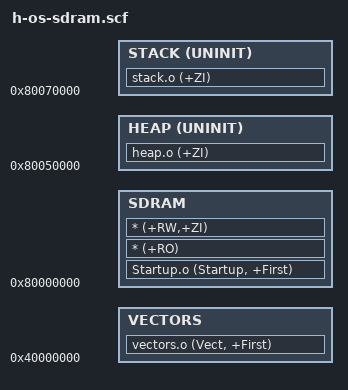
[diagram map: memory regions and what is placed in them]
;*
;*//**********************************************************************************
;*                                        H-OS
;*                                The Real-Time Kernel
;*                                   TASK MANAGEMENT
;*
;*                      (c) Copyright 2007-2077, Harriman Hao
;*                                 All Rights Reserved
;*
;**//*******************************************************************************//
;**//Filename:   @  h-os.scf                                             
;**//            @
;**//Revision:   @  1.0
;**//            @
;**//Data:       @  2008.7.16
;**//            @
;**//Editor:     @  harrimanhao
;**//*******************************************************************************//

ROM_LOAD 0x80000000
{
;*******SDRAM 0x8000 0000~~0x8007 FFFF   4m ***********

    SDRAM 0x80000000
    {
        Startup.o (Startup, +First)
        * (+RO)  
        * (+RW,+ZI)     
    }
    HEAP 0x80050000  UNINIT
    {
        heap.o  (+ZI)
    }    
    STACK 0x80070000 UNINIT
    {
        stack.o (+ZI)
    }


;*******FLASH 0x8100 0000~~0x811F FFFF   16m ************
;
;    HEAP 0x81000000  UNINIT
;    {
;        heap.o  (+ZI)
;    }    
;    STACK 0x81020000 UNINIT
;    {
;        stack.o (+ZI)
;    }
;    Sdram 0x81030000 0x8000 
;    {
;        * (+RW,+ZI)
;    } 
;
;
;*******RAM 0x4000 0000~~0x4000 3FFF************

    VECTORS 0x40000000
    {
        vectors.o (Vect, +First)
    }
}

